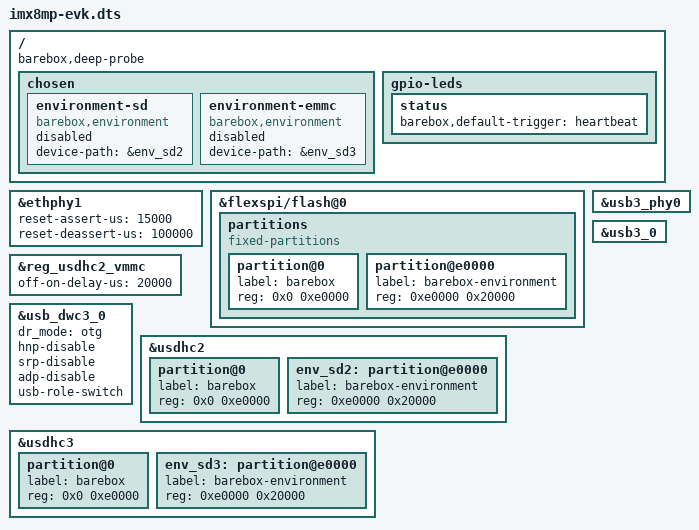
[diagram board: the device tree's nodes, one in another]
// SPDX-License-Identifier: (GPL-2.0 OR MIT)
/*
 * Copyright 2017 NXP
 * Copyright (C) 2017 Pengutronix, Oleksij Rempel <kernel@pengutronix.de>
 */

/dts-v1/;

#include <arm64/freescale/imx8mp-evk.dts>
#include "imx8mp.dtsi"

/ {
	barebox,deep-probe;

	chosen {
		environment-sd {
			compatible = "barebox,environment";
			device-path = &env_sd2;
			status = "disabled";
		};
		environment-emmc {
			compatible = "barebox,environment";
			device-path = &env_sd3;
			status = "disabled";
		};
	};

	gpio-leds {
		status {
			barebox,default-trigger = "heartbeat";
		};
	};
};

/delete-node/ &{/memory@40000000};

&ethphy1 {
	reset-assert-us = <15000>;
	reset-deassert-us = <100000>;
};

&{flexspi/flash@0} {
	partitions {
		compatible = "fixed-partitions";
		#address-cells = <1>;
		#size-cells = <1>;

		partition@0 {
			label = "barebox";
			reg = <0x0 0xe0000>;
		};

		partition@e0000 {
			label = "barebox-environment";
			reg = <0xe0000 0x20000>;
		};
	};

};

&reg_usdhc2_vmmc {
	off-on-delay-us = <20000>;
};

&usb3_phy0 {
	status = "okay";
};

&usb3_0 {
	status = "okay";
};

&usb_dwc3_0 {
	dr_mode = "otg";
	hnp-disable;
	srp-disable;
	adp-disable;
	usb-role-switch;
	status = "okay";
};

&usdhc2 {
	#address-cells = <1>;
	#size-cells = <1>;

	partition@0 {
		label = "barebox";
		reg = <0x0 0xe0000>;
	};

	env_sd2: partition@e0000 {
		label = "barebox-environment";
		reg = <0xe0000 0x20000>;
	};
};

&usdhc3 {
	#address-cells = <1>;
	#size-cells = <1>;

	partition@0 {
		label = "barebox";
		reg = <0x0 0xe0000>;
	};

	env_sd3: partition@e0000 {
		label = "barebox-environment";
		reg = <0xe0000 0x20000>;
	};
};
